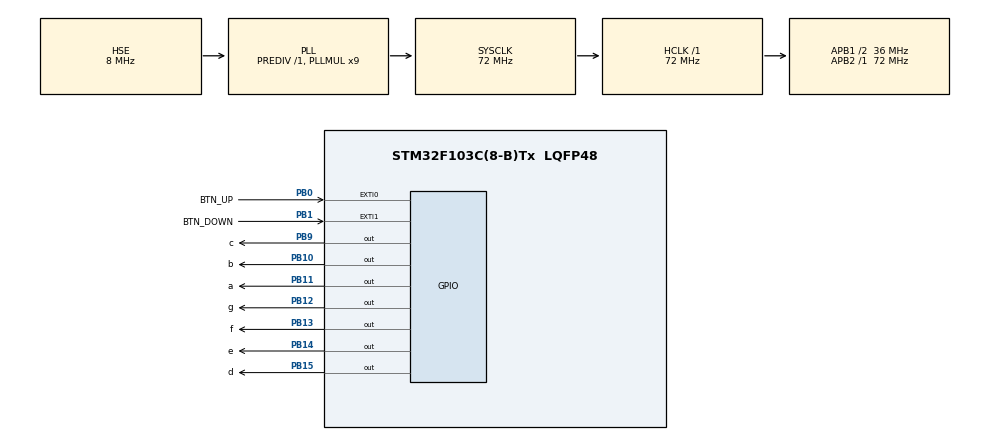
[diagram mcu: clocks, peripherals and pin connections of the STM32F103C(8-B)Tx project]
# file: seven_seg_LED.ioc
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Mcu.Family=STM32F1
Mcu.Name=STM32F103C(8-B)Tx
Mcu.Package=LQFP48
NVIC.EXTI0_IRQn=true\:1\:0\:true\:false\:true\:true\:true\:true
NVIC.EXTI1_IRQn=true\:2\:0\:true\:false\:true\:true\:true\:true
NVIC.PriorityGroup=NVIC_PRIORITYGROUP_4
PA13.Mode=Serial_Wire
PA13.Signal=SYS_JTMS-SWDIO
PA14.Mode=Serial_Wire
PA14.Signal=SYS_JTCK-SWCLK
PB0.GPIO_Label=BTN_UP
PB0.GPIO_ModeDefaultEXTI=GPIO_MODE_IT_FALLING
PB0.GPIO_PuPd=GPIO_PULLUP
PB0.Signal=GPXTI0
PB1.GPIO_Label=BTN_DOWN
PB1.GPIO_ModeDefaultEXTI=GPIO_MODE_IT_FALLING
PB1.GPIO_PuPd=GPIO_PULLUP
PB1.Signal=GPXTI1
PB10.GPIO_Label=b
PB10.Signal=GPIO_Output
PB11.GPIO_Label=a
PB11.Signal=GPIO_Output
PB12.GPIO_Label=g
PB12.Signal=GPIO_Output
PB13.GPIO_Label=f
PB13.Signal=GPIO_Output
PB14.GPIO_Label=e
PB14.Signal=GPIO_Output
PB15.GPIO_Label=d
PB15.Signal=GPIO_Output
PB9.GPIO_Label=c
PB9.Signal=GPIO_Output
PD0-OSC_IN.Mode=HSE-External-Oscillator
PD0-OSC_IN.Signal=RCC_OSC_IN
PD1-OSC_OUT.Mode=HSE-External-Oscillator
PD1-OSC_OUT.Signal=RCC_OSC_OUT
ProjectManager.HeapSize=0x200
ProjectManager.StackSize=0x400
ProjectManager.TargetToolchain=MDK-ARM V5.32
RCC.AHBFreq_Value=72000000
RCC.APB1CLKDivider=RCC_HCLK_DIV2
RCC.APB1Freq_Value=36000000
RCC.APB1TimFreq_Value=72000000
RCC.APB2Freq_Value=72000000
RCC.APB2TimFreq_Value=72000000
RCC.HCLKFreq_Value=72000000
RCC.PLLMUL=RCC_PLL_MUL9
RCC.PLLSourceVirtual=RCC_PLLSOURCE_HSE
RCC.SYSCLKFreq_VALUE=72000000
RCC.SYSCLKSource=RCC_SYSCLKSOURCE_PLLCLK
RCC.USBFreq_Value=72000000
board=custom

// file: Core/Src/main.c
/* USER CODE BEGIN Header */
/**
  ******************************************************************************
  * @file           : main.c
  * @brief          : Main program body
  ******************************************************************************
  * @attention
  *
  * Copyright (c) 2025 STMicroelectronics.
  * All rights reserved.
  *
  * This software is licensed under terms that can be found in the LICENSE file
  * in the root directory of this software component.
  * If no LICENSE file comes with this software, it is provided AS-IS.
  *
  ******************************************************************************
  */
/* USER CODE END Header */
#include "main.h"

void SystemClock_Config(void);
static void MX_GPIO_Init(void);
/* USER CODE BEGIN PFP */
/*

pb9 :c
pb10:b
pb11:a
pb12:g
pb13:f
pb14:e
pb15:d

*/
/* 0:0b1110111 1:0b0000011 2:0b1101110 3:0b1001111 4:0b0011011 5:0b1011101 6:0b1111101 7:0b0000111 8:0b1111111 9:0b1011111 */

const uint16_t digits[10] = { 0x77<<9 , 0x03<<9 , 0x6e<<9 , 0x4f<<9 ,
														0x1b<<9 , 0x5d<<9 , 0x7d<<9 , 0x07<<9 , 0x7f<<9 , 0x5f<<9};
uint16_t mask = 0x7f << 9;
uint8_t num = 0;
/* USER CODE END PFP */

/* USER CODE BEGIN 0 */
void HAL_GPIO_EXTI_Callback(uint16_t GPIO_Pin)
{
	if(GPIO_Pin==BTN_UP_Pin){
		if(num<9)num++;

	}else if(GPIO_Pin==BTN_DOWN_Pin){
		if(num>0)num--;

	}
	HAL_GPIO_WritePin(GPIOB, digits[num], GPIO_PIN_SET);
	HAL_GPIO_WritePin(GPIOB, mask & ~(digits[num]) , GPIO_PIN_RESET);

}
/* USER CODE END 0 */

int main(void)
{

  /* MCU Configuration--------------------------------------------------------*/

  /* Reset of all peripherals, Initializes the Flash interface and the Systick. */
  HAL_Init();

  /* Configure the system clock */
  SystemClock_Config();

  /* Initialize all configured peripherals */
  MX_GPIO_Init();

  /* Infinite loop */
  while (1)
  {

  }
}

void SystemClock_Config(void)
{
  RCC_OscInitTypeDef RCC_OscInitStruct = {0};
  RCC_ClkInitTypeDef RCC_ClkInitStruct = {0};

  /** Initializes the RCC Oscillators according to the specified parameters
  * in the RCC_OscInitTypeDef structure.
  */
  RCC_OscInitStruct.OscillatorType = RCC_OSCILLATORTYPE_HSE;
  RCC_OscInitStruct.HSEState = RCC_HSE_ON;
  RCC_OscInitStruct.HSEPredivValue = RCC_HSE_PREDIV_DIV1;
  RCC_OscInitStruct.HSIState = RCC_HSI_ON;
  RCC_OscInitStruct.PLL.PLLState = RCC_PLL_ON;
  RCC_OscInitStruct.PLL.PLLSource = RCC_PLLSOURCE_HSE;
  RCC_OscInitStruct.PLL.PLLMUL = RCC_PLL_MUL9;
  if (HAL_RCC_OscConfig(&RCC_OscInitStruct) != HAL_OK)
  {
    Error_Handler();
  }

  /** Initializes the CPU, AHB and APB buses clocks
  */
  RCC_ClkInitStruct.ClockType = RCC_CLOCKTYPE_HCLK|RCC_CLOCKTYPE_SYSCLK
                              |RCC_CLOCKTYPE_PCLK1|RCC_CLOCKTYPE_PCLK2;
  RCC_ClkInitStruct.SYSCLKSource = RCC_SYSCLKSOURCE_PLLCLK;
  RCC_ClkInitStruct.AHBCLKDivider = RCC_SYSCLK_DIV1;
  RCC_ClkInitStruct.APB1CLKDivider = RCC_HCLK_DIV2;
  RCC_ClkInitStruct.APB2CLKDivider = RCC_HCLK_DIV1;

  if (HAL_RCC_ClockConfig(&RCC_ClkInitStruct, FLASH_LATENCY_2) != HAL_OK)
  {
    Error_Handler();
  }
}

static void MX_GPIO_Init(void)
{
  GPIO_InitTypeDef GPIO_InitStruct = {0};

  /* GPIO Ports Clock Enable */
  __HAL_RCC_GPIOD_CLK_ENABLE();
  __HAL_RCC_GPIOB_CLK_ENABLE();
  __HAL_RCC_GPIOA_CLK_ENABLE();

  /*Configure GPIO pin Output Level */
  HAL_GPIO_WritePin(GPIOB, b_Pin|a_Pin|g_Pin|f_Pin
                          |e_Pin|d_Pin|c_Pin, GPIO_PIN_RESET);

  /*Configure GPIO pins : BTN_UP_Pin BTN_DOWN_Pin */
  GPIO_InitStruct.Pin = BTN_UP_Pin|BTN_DOWN_Pin;
  GPIO_InitStruct.Mode = GPIO_MODE_IT_FALLING;
  GPIO_InitStruct.Pull = GPIO_PULLUP;
  HAL_GPIO_Init(GPIOB, &GPIO_InitStruct);

  /*Configure GPIO pins : b_Pin a_Pin g_Pin f_Pin
                           e_Pin d_Pin c_Pin */
  GPIO_InitStruct.Pin = b_Pin|a_Pin|g_Pin|f_Pin
                          |e_Pin|d_Pin|c_Pin;
  GPIO_InitStruct.Mode = GPIO_MODE_OUTPUT_PP;
  GPIO_InitStruct.Pull = GPIO_NOPULL;
  GPIO_InitStruct.Speed = GPIO_SPEED_FREQ_LOW;
  HAL_GPIO_Init(GPIOB, &GPIO_InitStruct);

  /* EXTI interrupt init*/
  HAL_NVIC_SetPriority(EXTI0_IRQn, 1, 0);
  HAL_NVIC_EnableIRQ(EXTI0_IRQn);

  HAL_NVIC_SetPriority(EXTI1_IRQn, 2, 0);
  HAL_NVIC_EnableIRQ(EXTI1_IRQn);

}

void Error_Handler(void)
{
  __disable_irq();
  while (1)
  {
  }
}
